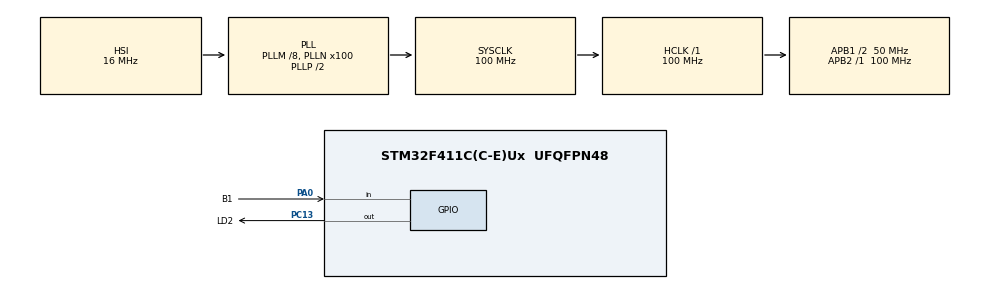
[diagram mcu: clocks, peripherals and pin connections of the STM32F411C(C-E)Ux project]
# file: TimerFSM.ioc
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Mcu.Family=STM32F4
Mcu.Name=STM32F411C(C-E)Ux
Mcu.Package=UFQFPN48
NVIC.PriorityGroup=NVIC_PRIORITYGROUP_4
NVIC.TIM1_UP_TIM10_IRQn=true\:0\:0\:false\:false\:true\:true\:true
PA0-WKUP.GPIO_Label=B1
PA0-WKUP.GPIO_PuPd=GPIO_PULLUP
PA0-WKUP.Signal=GPIO_Input
PA13.Mode=Serial_Wire
PA13.Signal=SYS_JTMS-SWDIO
PA14.Mode=Serial_Wire
PA14.Signal=SYS_JTCK-SWCLK
PC13-ANTI_TAMP.GPIO_Label=LD2
PC13-ANTI_TAMP.Signal=GPIO_Output
PH0\ -\ OSC_IN.Mode=HSE-External-Clock-Source
PH0\ -\ OSC_IN.Signal=RCC_OSC_IN
PH1\ -\ OSC_OUT.Mode=HSE-External-Clock-Source
PH1\ -\ OSC_OUT.Signal=RCC_OSC_OUT
ProjectManager.HeapSize=0x200
ProjectManager.StackSize=0x400
ProjectManager.TargetToolchain=MDK-ARM V5.27
RCC.48MHZClocksFreq_Value=50000000
RCC.AHBFreq_Value=100000000
RCC.APB1CLKDivider=RCC_HCLK_DIV2
RCC.APB1Freq_Value=50000000
RCC.APB1TimFreq_Value=100000000
RCC.APB2Freq_Value=100000000
RCC.APB2TimFreq_Value=100000000
RCC.CortexFreq_Value=100000000
RCC.HCLKFreq_Value=100000000
RCC.HSE_VALUE=25000000
RCC.HSI_VALUE=16000000
RCC.LSE_VALUE=32768
RCC.PLLM=8
RCC.PLLN=100
RCC.SYSCLKFreq_VALUE=100000000
RCC.SYSCLKSource=RCC_SYSCLKSOURCE_PLLCLK
RCC.VCOOutputFreq_Value=200000000
TIM10.Period=299
TIM10.Prescaler=9999
VP_TIM10_VS_ClockSourceINT.Mode=Enable_Timer
board=custom

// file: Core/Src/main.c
/* USER CODE BEGIN Header */
/**
  ******************************************************************************
  * @file           : main.c
  * @brief          : Main program body
  ******************************************************************************
  * @attention
  *
  * <h2><center>&copy; Copyright (c) 2021 STMicroelectronics.
  * All rights reserved.</center></h2>
  *
  * This software component is licensed by ST under BSD 3-Clause license,
  * the "License"; You may not use this file except in compliance with the
  * License. You may obtain a copy of the License at:
  *                        opensource.org/licenses/BSD-3-Clause
  *
  ******************************************************************************
  */
/* USER CODE END Header */
#include "main.h"
#include "tim.h"
#include "gpio.h"

/* USER CODE BEGIN PTD */
typedef enum
{
	KEY_CHECK=0,
	KEY_COMFIRM,
	KEY_RELEASE
}KEY_STATE;
/* USER CODE END PTD */

/* USER CODE BEGIN PV */
KEY_STATE KeyState=KEY_CHECK;
uint8_t KeyFlag=0;
int i=1;
/* USER CODE END PV */

void SystemClock_Config(void);

int main(void)
{

  /* MCU Configuration--------------------------------------------------------*/

  /* Reset of all peripherals, Initializes the Flash interface and the Systick. */
  HAL_Init();

  /* Configure the system clock */
  SystemClock_Config();

  /* Initialize all configured peripherals */
  MX_GPIO_Init();
  MX_TIM10_Init();
  /* USER CODE BEGIN 2 */
__HAL_TIM_CLEAR_IT(&htim10,TIM_IT_UPDATE);
HAL_TIM_Base_Start_IT(&htim10);
  /* USER CODE END 2 */

  /* Infinite loop */
  while (1)
  {

    /* USER CODE BEGIN 3 */
		if(KeyFlag==1)
		{
			if(i<3)
			{i++;}
			else
			{i=1;}
			KeyFlag=0;

		}
			switch(i)
		{
			case 1:
			{
					HAL_GPIO_TogglePin(LD2_GPIO_Port,LD2_Pin);
				HAL_Delay(1000);
			}break;
			case 2:
			{
					HAL_GPIO_TogglePin(LD2_GPIO_Port,LD2_Pin);
				HAL_Delay(100);
			}break;
			case 3:
			{
					HAL_GPIO_TogglePin(LD2_GPIO_Port,LD2_Pin);
				HAL_Delay(25);
			}break;
			default :break;
		}
  }
  /* USER CODE END 3 */
}

void SystemClock_Config(void)
{
  RCC_OscInitTypeDef RCC_OscInitStruct = {0};
  RCC_ClkInitTypeDef RCC_ClkInitStruct = {0};

  /** Configure the main internal regulator output voltage
  */
  __HAL_RCC_PWR_CLK_ENABLE();
  __HAL_PWR_VOLTAGESCALING_CONFIG(PWR_REGULATOR_VOLTAGE_SCALE1);
  /** Initializes the RCC Oscillators according to the specified parameters
  * in the RCC_OscInitTypeDef structure.
  */
  RCC_OscInitStruct.OscillatorType = RCC_OSCILLATORTYPE_HSI;
  RCC_OscInitStruct.HSIState = RCC_HSI_ON;
  RCC_OscInitStruct.HSICalibrationValue = RCC_HSICALIBRATION_DEFAULT;
  RCC_OscInitStruct.PLL.PLLState = RCC_PLL_ON;
  RCC_OscInitStruct.PLL.PLLSource = RCC_PLLSOURCE_HSI;
  RCC_OscInitStruct.PLL.PLLM = 8;
  RCC_OscInitStruct.PLL.PLLN = 100;
  RCC_OscInitStruct.PLL.PLLP = RCC_PLLP_DIV2;
  RCC_OscInitStruct.PLL.PLLQ = 4;
  if (HAL_RCC_OscConfig(&RCC_OscInitStruct) != HAL_OK)
  {
    Error_Handler();
  }
  /** Initializes the CPU, AHB and APB buses clocks
  */
  RCC_ClkInitStruct.ClockType = RCC_CLOCKTYPE_HCLK|RCC_CLOCKTYPE_SYSCLK
                              |RCC_CLOCKTYPE_PCLK1|RCC_CLOCKTYPE_PCLK2;
  RCC_ClkInitStruct.SYSCLKSource = RCC_SYSCLKSOURCE_PLLCLK;
  RCC_ClkInitStruct.AHBCLKDivider = RCC_SYSCLK_DIV1;
  RCC_ClkInitStruct.APB1CLKDivider = RCC_HCLK_DIV2;
  RCC_ClkInitStruct.APB2CLKDivider = RCC_HCLK_DIV1;

  if (HAL_RCC_ClockConfig(&RCC_ClkInitStruct, FLASH_LATENCY_3) != HAL_OK)
  {
    Error_Handler();
  }
}

/* USER CODE BEGIN 4 */
void HAL_TIM_PeriodElapsedCallback(TIM_HandleTypeDef*htim)
{
	if(htim->Instance==TIM10)
	{
		switch(KeyState)
		{
			case KEY_CHECK:
			{
				if(HAL_GPIO_ReadPin(B1_GPIO_Port,B1_Pin)==GPIO_PIN_RESET)
				{KeyState=KEY_COMFIRM;}
			}break;
			case KEY_COMFIRM:
			{
				if(HAL_GPIO_ReadPin(B1_GPIO_Port,B1_Pin)==GPIO_PIN_RESET)
				{
					KeyState=KEY_RELEASE;
					KeyFlag=1;
				}
				else{KeyState=KEY_CHECK;}
			}break;
			case KEY_RELEASE:
			{
				if(HAL_GPIO_ReadPin(B1_GPIO_Port,B1_Pin)==GPIO_PIN_RESET)
				{KeyState=KEY_CHECK;}
			}break;
			default : break;
		}
   }
}
/* USER CODE END 4 */

void Error_Handler(void)
{
  __disable_irq();
  while (1)
  {
  }
}

/************************ (C) COPYRIGHT STMicroelectronics *****END OF FILE****/
